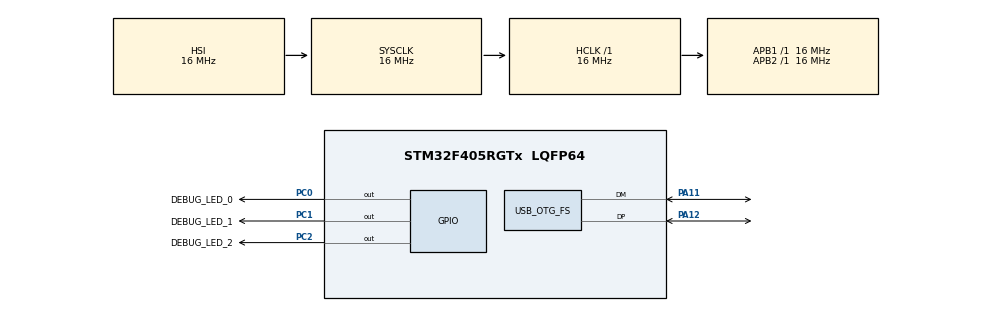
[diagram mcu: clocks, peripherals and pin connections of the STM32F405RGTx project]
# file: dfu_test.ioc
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Mcu.Family=STM32F4
Mcu.Name=STM32F405RGTx
Mcu.Package=LQFP64
NVIC.PriorityGroup=NVIC_PRIORITYGROUP_4
PA11.Mode=Device_Only
PA11.Signal=USB_OTG_FS_DM
PA12.Mode=Device_Only
PA12.Signal=USB_OTG_FS_DP
PA13.Mode=Serial_Wire
PA13.Signal=SYS_JTMS-SWDIO
PA14.Mode=Serial_Wire
PA14.Signal=SYS_JTCK-SWCLK
PC0.GPIO_Label=DEBUG_LED_0
PC0.Signal=GPIO_Output
PC1.GPIO_Label=DEBUG_LED_1
PC1.Signal=GPIO_Output
PC2.GPIO_Label=DEBUG_LED_2
PC2.Signal=GPIO_Output
PH0-OSC_IN.Mode=HSE-External-Oscillator
PH0-OSC_IN.Signal=RCC_OSC_IN
PH1-OSC_OUT.Mode=HSE-External-Oscillator
PH1-OSC_OUT.Signal=RCC_OSC_OUT
ProjectManager.HeapSize=0x200
ProjectManager.StackSize=0x400
ProjectManager.TargetToolchain=STM32CubeIDE
RCC.48MHZClocksFreq_Value=48000000
RCC.AHBFreq_Value=16000000
RCC.APB1Freq_Value=16000000
RCC.APB2Freq_Value=16000000
RCC.CortexFreq_Value=16000000
RCC.HSE_VALUE=25000000
RCC.HSI_VALUE=16000000
RCC.LSE_VALUE=32768
RCC.PLLM=15
RCC.PLLN=144
RCC.PLLQ=5
RCC.SYSCLKFreq_VALUE=16000000
RCC.VCOOutputFreq_Value=240000000
USB_OTG_FS.VirtualMode=Device_Only
board=custom

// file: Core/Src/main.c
/* USER CODE BEGIN Header */
/**
  ******************************************************************************
  * @file           : main.c
  * @brief          : Main program body
  ******************************************************************************
  * @attention
  *
  * Copyright (c) 2025 STMicroelectronics.
  * All rights reserved.
  *
  * This software is licensed under terms that can be found in the LICENSE file
  * in the root directory of this software component.
  * If no LICENSE file comes with this software, it is provided AS-IS.
  *
  ******************************************************************************
  */
/* USER CODE END Header */
#include "main.h"

PCD_HandleTypeDef hpcd_USB_OTG_FS;

void SystemClock_Config(void);
static void MX_GPIO_Init(void);
static void MX_USB_OTG_FS_PCD_Init(void);

int main(void)
{

  /* MCU Configuration--------------------------------------------------------*/

  /* Reset of all peripherals, Initializes the Flash interface and the Systick. */
  HAL_Init();

  /* Configure the system clock */
  SystemClock_Config();

  /* Initialize all configured peripherals */
  MX_GPIO_Init();
  MX_USB_OTG_FS_PCD_Init();

  /* Infinite loop */
  while (1)
  {

    /* USER CODE BEGIN 3 */
	  // Turn on some heartbeat LEDS!!!!!
	  HAL_GPIO_TogglePin(GPIOC, DEBUG_LED_0_Pin);
	  HAL_Delay(100);
	  HAL_GPIO_TogglePin(GPIOC, DEBUG_LED_0_Pin);
	  HAL_GPIO_TogglePin(GPIOC, DEBUG_LED_1_Pin);
	  HAL_Delay(100);
	  HAL_GPIO_TogglePin(GPIOC, DEBUG_LED_1_Pin);
	  HAL_GPIO_TogglePin(GPIOC, DEBUG_LED_2_Pin);
	  HAL_Delay(100);
	  HAL_GPIO_TogglePin(GPIOC, DEBUG_LED_2_Pin);
  }
  /* USER CODE END 3 */
}

void SystemClock_Config(void)
{
  RCC_OscInitTypeDef RCC_OscInitStruct = {0};
  RCC_ClkInitTypeDef RCC_ClkInitStruct = {0};

  /** Configure the main internal regulator output voltage
  */
  __HAL_RCC_PWR_CLK_ENABLE();
  __HAL_PWR_VOLTAGESCALING_CONFIG(PWR_REGULATOR_VOLTAGE_SCALE1);

  /** Initializes the RCC Oscillators according to the specified parameters
  * in the RCC_OscInitTypeDef structure.
  */
  RCC_OscInitStruct.OscillatorType = RCC_OSCILLATORTYPE_HSI|RCC_OSCILLATORTYPE_HSE;
  RCC_OscInitStruct.HSEState = RCC_HSE_ON;
  RCC_OscInitStruct.HSIState = RCC_HSI_ON;
  RCC_OscInitStruct.HSICalibrationValue = RCC_HSICALIBRATION_DEFAULT;
  RCC_OscInitStruct.PLL.PLLState = RCC_PLL_ON;
  RCC_OscInitStruct.PLL.PLLSource = RCC_PLLSOURCE_HSE;
  RCC_OscInitStruct.PLL.PLLM = 15;
  RCC_OscInitStruct.PLL.PLLN = 144;
  RCC_OscInitStruct.PLL.PLLP = RCC_PLLP_DIV2;
  RCC_OscInitStruct.PLL.PLLQ = 5;
  if (HAL_RCC_OscConfig(&RCC_OscInitStruct) != HAL_OK)
  {
    Error_Handler();
  }

  /** Initializes the CPU, AHB and APB buses clocks
  */
  RCC_ClkInitStruct.ClockType = RCC_CLOCKTYPE_HCLK|RCC_CLOCKTYPE_SYSCLK
                              |RCC_CLOCKTYPE_PCLK1|RCC_CLOCKTYPE_PCLK2;
  RCC_ClkInitStruct.SYSCLKSource = RCC_SYSCLKSOURCE_HSI;
  RCC_ClkInitStruct.AHBCLKDivider = RCC_SYSCLK_DIV1;
  RCC_ClkInitStruct.APB1CLKDivider = RCC_HCLK_DIV1;
  RCC_ClkInitStruct.APB2CLKDivider = RCC_HCLK_DIV1;

  if (HAL_RCC_ClockConfig(&RCC_ClkInitStruct, FLASH_LATENCY_0) != HAL_OK)
  {
    Error_Handler();
  }
}

static void MX_USB_OTG_FS_PCD_Init(void)
{

  hpcd_USB_OTG_FS.Instance = USB_OTG_FS;
  hpcd_USB_OTG_FS.Init.dev_endpoints = 4;
  hpcd_USB_OTG_FS.Init.speed = PCD_SPEED_FULL;
  hpcd_USB_OTG_FS.Init.dma_enable = DISABLE;
  hpcd_USB_OTG_FS.Init.phy_itface = PCD_PHY_EMBEDDED;
  hpcd_USB_OTG_FS.Init.Sof_enable = DISABLE;
  hpcd_USB_OTG_FS.Init.low_power_enable = DISABLE;
  hpcd_USB_OTG_FS.Init.lpm_enable = DISABLE;
  hpcd_USB_OTG_FS.Init.vbus_sensing_enable = DISABLE;
  hpcd_USB_OTG_FS.Init.use_dedicated_ep1 = DISABLE;
  if (HAL_PCD_Init(&hpcd_USB_OTG_FS) != HAL_OK)
  {
    Error_Handler();
  }

}

static void MX_GPIO_Init(void)
{
  GPIO_InitTypeDef GPIO_InitStruct = {0};

  /* GPIO Ports Clock Enable */
  __HAL_RCC_GPIOH_CLK_ENABLE();
  __HAL_RCC_GPIOC_CLK_ENABLE();
  __HAL_RCC_GPIOA_CLK_ENABLE();

  /*Configure GPIO pin Output Level */
  HAL_GPIO_WritePin(GPIOC, DEBUG_LED_0_Pin|DEBUG_LED_1_Pin|DEBUG_LED_2_Pin, GPIO_PIN_RESET);

  /*Configure GPIO pins : DEBUG_LED_0_Pin DEBUG_LED_1_Pin DEBUG_LED_2_Pin */
  GPIO_InitStruct.Pin = DEBUG_LED_0_Pin|DEBUG_LED_1_Pin|DEBUG_LED_2_Pin;
  GPIO_InitStruct.Mode = GPIO_MODE_OUTPUT_PP;
  GPIO_InitStruct.Pull = GPIO_NOPULL;
  GPIO_InitStruct.Speed = GPIO_SPEED_FREQ_LOW;
  HAL_GPIO_Init(GPIOC, &GPIO_InitStruct);

}

void Error_Handler(void)
{
  __disable_irq();
  while (1)
  {
  }
}
